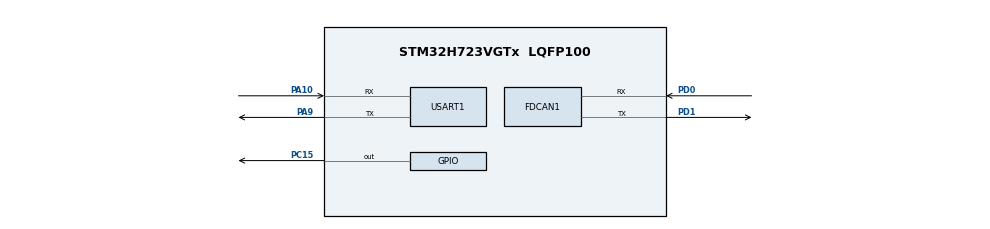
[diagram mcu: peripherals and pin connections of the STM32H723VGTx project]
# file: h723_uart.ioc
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CORTEX_M7.default_mode_Activation=1
FDCAN1.AutoRetransmission=ENABLE
FDCAN1.CalculateBaudRateNominal=1000000
FDCAN1.CalculateTimeBitNominal=1000
FDCAN1.CalculateTimeQuantumNominal=83.33333333333333
FDCAN1.Mode=FDCAN_MODE_NORMAL
FDCAN1.NominalPrescaler=8
FDCAN1.NominalTimeSeg1=9
FDCAN1.NominalTimeSeg2=2
FDCAN1.RxFifo0ElmtsNbr=64
FDCAN1.StdFiltersNbr=1
FDCAN1.TxBuffersNbr=1
FDCAN1.TxEventsNbr=0
FDCAN1.TxFifoQueueElmtsNbr=4
Mcu.Family=STM32H7
Mcu.Name=STM32H723VGTx
Mcu.Package=LQFP100
NVIC.FDCAN1_IT0_IRQn=true\:0\:0\:false\:false\:true\:true\:true\:true
NVIC.PriorityGroup=NVIC_PRIORITYGROUP_4
NVIC.USART1_IRQn=true\:0\:0\:false\:false\:true\:true\:true\:true
PA10.Mode=Asynchronous
PA10.Signal=USART1_RX
PA13(JTMS/SWDIO).Mode=Serial_Wire
PA13(JTMS/SWDIO).Signal=DEBUG_JTMS-SWDIO
PA14(JTCK/SWCLK).Mode=Serial_Wire
PA14(JTCK/SWCLK).Signal=DEBUG_JTCK-SWCLK
PA9.Mode=Asynchronous
PA9.Signal=USART1_TX
PC15-OSC32_OUT.Signal=GPIO_Output
PD0.Mode=FDCAN_Activate
PD0.Signal=FDCAN1_RX
PD1.Mode=FDCAN_Activate
PD1.Signal=FDCAN1_TX
PH0-OSC_IN.Mode=HSE-External-Oscillator
PH0-OSC_IN.Signal=RCC_OSC_IN
PH1-OSC_OUT.Mode=HSE-External-Oscillator
PH1-OSC_OUT.Signal=RCC_OSC_OUT
ProjectManager.HeapSize=0x200
ProjectManager.StackSize=0x400
ProjectManager.TargetToolchain=CMake
RCC.ADCFreq_Value=129000000
RCC.APB1Freq_Value=96000000
RCC.APB2Freq_Value=96000000
RCC.APB3Freq_Value=96000000
RCC.APB4Freq_Value=96000000
RCC.CortexFreq_Value=192000000
RCC.D1PPRE=RCC_APB3_DIV2
RCC.D2PPRE1=RCC_APB1_DIV2
RCC.D2PPRE2=RCC_APB2_DIV2
RCC.D3PPRE=RCC_APB4_DIV2
RCC.DIVM1=4
RCC.DIVN1=12
RCC.DIVP1=1
RCC.HCLKFreq_Value=192000000
RCC.PLL2FRACN=0
RCC.PLL3FRACN=0
RCC.PLLFRACN=0
RCC.SYSCLKFreq_VALUE=192000000
RCC.SYSCLKSource=RCC_SYSCLKSOURCE_PLLCLK
RCC.USBFreq_Value=96000000
USART1.VirtualMode-Asynchronous=VM_ASYNC
VP_MEMORYMAP_VS_MEMORYMAP.Mode=CurAppReg
board=custom

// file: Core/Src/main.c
/* USER CODE BEGIN Header */
/**
  ******************************************************************************
  * @file           : main.c
  * @brief          : Main program body
  ******************************************************************************
  * @attention
  *
  * Copyright (c) 2026 STMicroelectronics.
  * All rights reserved.
  *
  * This software is licensed under terms that can be found in the LICENSE file
  * in the root directory of this software component.
  * If no LICENSE file comes with this software, it is provided AS-IS.
  *
  ******************************************************************************
  */
/* USER CODE END Header */
#include "main.h"
#include "fdcan.h"
#include "memorymap.h"
#include "usart.h"
#include "gpio.h"

/* USER CODE BEGIN Includes */
#include <stdbool.h>
#include "app_entry.h"
#include "bsp_fdcan.h"
//#include "pid.hpp"
/* USER CODE END Includes */

/* USER CODE BEGIN PD */
/*

*/

/* USER CODE END PD */

void SystemClock_Config(void);
static void MPU_Config(void);

int main(void)
{

  /* MPU Configuration--------------------------------------------------------*/
  MPU_Config();

  /* MCU Configuration--------------------------------------------------------*/

  /* Reset of all peripherals, Initializes the Flash interface and the Systick. */
  HAL_Init();

  /* Configure the system clock */
  SystemClock_Config();

  /* Initialize all configured peripherals */
  MX_GPIO_Init();
  MX_USART1_UART_Init();
  MX_FDCAN1_Init();
  /* USER CODE BEGIN 2 */
  //初始化应用程序
  App_Init();
  //初始化滤波器
  FDCAN_FILTER_MASK_Config(&hfdcan1, 0x000, 0x000);
  //初始化can总线
  FDCAN_Init(&hfdcan1);

//  uint8_t txdata[8] = {0};

//  uint32_t last_tx_ms = HAL_GetTick();

  /* USER CODE END 2 */

  /* Infinite loop */
  /* USER CODE BEGIN WHILE */
  while (1)
  {
    HAL_GPIO_WritePin(GPIOC,GPIO_PIN_15,GPIO_PIN_SET);
    App_Poll();
    /* USER CODE END WHILE */
/*    uint32_t now_ms = HAL_GetTick();

    if ((uint32_t)(now_ms - last_tx_ms) >= 1U)
    {
        last_tx_ms = now_ms;
        PID_output = PID_Step(&pid, target_speed,GM6020_feedback[0].speed,0.001f);
        uint16_t bits = (uint16_t)PID_output;
        txdata[0] = (uint8_t)(bits >> 8);
        txdata[1] = (uint8_t)(bits & 0xFFU);
        FDCAN_Send_Data(&hfdcan1,0x1FF,txdata,8);

        count_ms++;
    }
    */
  }
}

void SystemClock_Config(void)
{
  RCC_OscInitTypeDef RCC_OscInitStruct = {0};
  RCC_ClkInitTypeDef RCC_ClkInitStruct = {0};

  /** Supply configuration update enable
  */
  HAL_PWREx_ConfigSupply(PWR_LDO_SUPPLY);

  /** Configure the main internal regulator output voltage
  */
  __HAL_PWR_VOLTAGESCALING_CONFIG(PWR_REGULATOR_VOLTAGE_SCALE1);

  while(!__HAL_PWR_GET_FLAG(PWR_FLAG_VOSRDY)) {}

  /** Initializes the RCC Oscillators according to the specified parameters
  * in the RCC_OscInitTypeDef structure.
  */
  RCC_OscInitStruct.OscillatorType = RCC_OSCILLATORTYPE_HSI;
  RCC_OscInitStruct.HSIState = RCC_HSI_DIV1;
  RCC_OscInitStruct.HSICalibrationValue = 64;
  RCC_OscInitStruct.PLL.PLLState = RCC_PLL_ON;
  RCC_OscInitStruct.PLL.PLLSource = RCC_PLLSOURCE_HSI;
  RCC_OscInitStruct.PLL.PLLM = 4;
  RCC_OscInitStruct.PLL.PLLN = 12;
  RCC_OscInitStruct.PLL.PLLP = 1;
  RCC_OscInitStruct.PLL.PLLQ = 2;
  RCC_OscInitStruct.PLL.PLLR = 2;
  RCC_OscInitStruct.PLL.PLLRGE = RCC_PLL1VCIRANGE_3;
  RCC_OscInitStruct.PLL.PLLVCOSEL = RCC_PLL1VCOWIDE;
  RCC_OscInitStruct.PLL.PLLFRACN = 0;
  if (HAL_RCC_OscConfig(&RCC_OscInitStruct) != HAL_OK)
  {
    Error_Handler();
  }

  /** Initializes the CPU, AHB and APB buses clocks
  */
  RCC_ClkInitStruct.ClockType = RCC_CLOCKTYPE_HCLK|RCC_CLOCKTYPE_SYSCLK
                              |RCC_CLOCKTYPE_PCLK1|RCC_CLOCKTYPE_PCLK2
                              |RCC_CLOCKTYPE_D3PCLK1|RCC_CLOCKTYPE_D1PCLK1;
  RCC_ClkInitStruct.SYSCLKSource = RCC_SYSCLKSOURCE_PLLCLK;
  RCC_ClkInitStruct.SYSCLKDivider = RCC_SYSCLK_DIV1;
  RCC_ClkInitStruct.AHBCLKDivider = RCC_HCLK_DIV1;
  RCC_ClkInitStruct.APB3CLKDivider = RCC_APB3_DIV2;
  RCC_ClkInitStruct.APB1CLKDivider = RCC_APB1_DIV2;
  RCC_ClkInitStruct.APB2CLKDivider = RCC_APB2_DIV2;
  RCC_ClkInitStruct.APB4CLKDivider = RCC_APB4_DIV2;

  if (HAL_RCC_ClockConfig(&RCC_ClkInitStruct, FLASH_LATENCY_2) != HAL_OK)
  {
    Error_Handler();
  }
}

/* USER CODE BEGIN 4 */

void HAL_FDCAN_RxFifo0Callback(FDCAN_HandleTypeDef *hfdcan, uint32_t RxFifo0ITs)
{
  BSP_FDCAN_RxFifo0Callback(hfdcan, RxFifo0ITs);
}
/* USER CODE END 4 */

 /* MPU Configuration */

void MPU_Config(void)
{
  MPU_Region_InitTypeDef MPU_InitStruct = {0};

  /* Disables the MPU */
  HAL_MPU_Disable();

  /** Initializes and configures the Region and the memory to be protected
  */
  MPU_InitStruct.Enable = MPU_REGION_ENABLE;
  MPU_InitStruct.Number = MPU_REGION_NUMBER0;
  MPU_InitStruct.BaseAddress = 0x0;
  MPU_InitStruct.Size = MPU_REGION_SIZE_4GB;
  MPU_InitStruct.SubRegionDisable = 0x87;
  MPU_InitStruct.TypeExtField = MPU_TEX_LEVEL0;
  MPU_InitStruct.AccessPermission = MPU_REGION_NO_ACCESS;
  MPU_InitStruct.DisableExec = MPU_INSTRUCTION_ACCESS_DISABLE;
  MPU_InitStruct.IsShareable = MPU_ACCESS_SHAREABLE;
  MPU_InitStruct.IsCacheable = MPU_ACCESS_NOT_CACHEABLE;
  MPU_InitStruct.IsBufferable = MPU_ACCESS_NOT_BUFFERABLE;

  HAL_MPU_ConfigRegion(&MPU_InitStruct);
  /* Enables the MPU */
  HAL_MPU_Enable(MPU_PRIVILEGED_DEFAULT);

}

void Error_Handler(void)
{
  __disable_irq();
  while (1)
  {
  }
}
